VERSION "OBD2_SAE_J1979_Mode01"

NS_ :

BS_:

BU_: OBD_Tester Engine_ECU

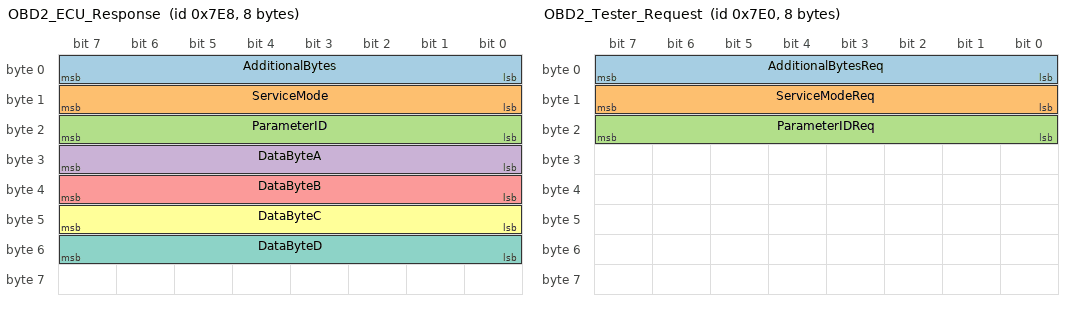
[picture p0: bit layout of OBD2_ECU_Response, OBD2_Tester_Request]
BO_ 2024 OBD2_ECU_Response: 8 Engine_ECU
 SG_ AdditionalBytes : 0|8@1+ (1,0) [0|7] "" OBD_Tester
 SG_ ServiceMode : 8|8@1+ (1,0) [0|255] "" OBD_Tester
 SG_ ParameterID : 16|8@1+ (1,0) [0|255] "" OBD_Tester
 SG_ DataByteA : 24|8@1+ (1,0) [0|255] "" OBD_Tester
 SG_ DataByteB : 32|8@1+ (1,0) [0|255] "" OBD_Tester
 SG_ DataByteC : 40|8@1+ (1,0) [0|255] "" OBD_Tester
 SG_ DataByteD : 48|8@1+ (1,0) [0|255] "" OBD_Tester

BO_ 2016 OBD2_Tester_Request: 8 OBD_Tester
 SG_ AdditionalBytesReq : 0|8@1+ (1,0) [0|7] "" Engine_ECU
 SG_ ServiceModeReq : 8|8@1+ (1,0) [0|255] "" Engine_ECU
 SG_ ParameterIDReq : 16|8@1+ (1,0) [0|255] "" Engine_ECU

CM_ "Standard OBD-II SAE J1979 Mode 01 Request/Response Diagnostic CAN Database (0x7DF Broadcast, 0x7E0 ECU Request, 0x7E8 ECU Response)";
